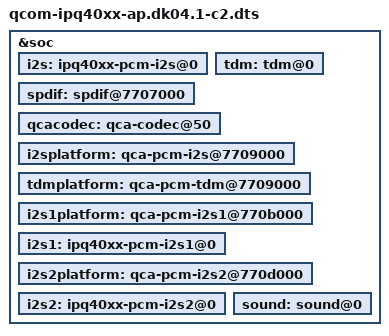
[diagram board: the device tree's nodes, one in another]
/* Copyright (c) 2015, The Linux Foundation. All rights reserved.
 *
 * Permission to use, copy, modify, and/or distribute this software for any
 * purpose with or without fee is hereby granted, provided that the above
 * copyright notice and this permission notice appear in all copies.
 *
 * THE SOFTWARE IS PROVIDED "AS IS" AND THE AUTHOR DISCLAIMS ALL WARRANTIES
 * WITH REGARD TO THIS SOFTWARE INCLUDING ALL IMPLIED WARRANTIES OF
 * MERCHANTABILITY AND FITNESS. IN NO EVENT SHALL THE AUTHOR BE LIABLE FOR
 * ANY SPECIAL, DIRECT, INDIRECT, OR CONSEQUENTIAL DAMAGES OR ANY DAMAGES
 * WHATSOEVER RESULTING FROM LOSS OF USE, DATA OR PROFITS, WHETHER IN AN
 * ACTION OF CONTRACT, NEGLIGENCE OR OTHER TORTIOUS ACTION, ARISING OUT OF
 * OR IN CONNECTION WITH THE USE OR PERFORMANCE OF THIS SOFTWARE.
 *
 */

#include "qcom-ipq40xx-ap.dk04.1.dtsi"
#include "qcom-ipq40xx-audio.dtsi"

&soc {
	/* Enable Audio Interfaces */
	i2s: ipq40xx-pcm-i2s@0 {
		status = "ok";
	};

	tdm: tdm@0 {
		status = "ok";
	};

	spdif: spdif@7707000 {
		status = "ok";
	};

	qcacodec: qca-codec@50 {
		status = "ok";
	};

	i2splatform: qca-pcm-i2s@7709000 {
		status = "ok";
	};

	tdmplatform: qca-pcm-tdm@7709000 {
		status = "ok";
	};

	i2s1platform: qca-pcm-i2s1@770b000 {
		status = "ok";
	};

	i2s1: ipq40xx-pcm-i2s1@0 {
		status = "ok";
	};

	i2s2platform: qca-pcm-i2s2@770d000 {
		status = "ok";
	};

	i2s2: ipq40xx-pcm-i2s2@0 {
		status = "ok";
	};

	sound: sound@0 {
		status = "ok";
	};
};
